VERSION ""

NS_ :

BS_:

BU_: Master pingpong

BO_ 386 pingpong_TPDO1: 4 pingpong
 SG_ UNSIGNED32_sent_from_slave : 0|32@1+ (1,0) [0|4294967295] "" Master

BO_ 514 pingpong_RPDO1: 4 Master
 SG_ UNSIGNED32_received_by_slave : 0|32@1+ (1,0) [0|4294967295] "" pingpong

BO_ 1794 pingpong_Heartbeat: 1 pingpong
 SG_ NMT_State : 0|7@1+ (1,0) [0|127] "" Master

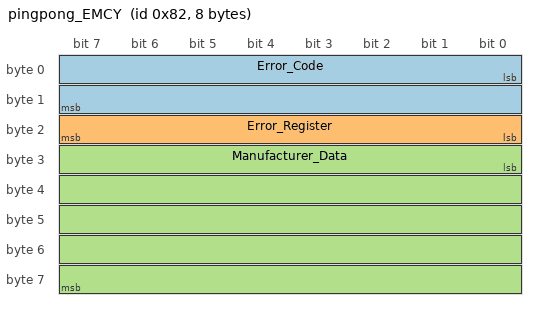
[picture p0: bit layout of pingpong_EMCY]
BO_ 130 pingpong_EMCY: 8 pingpong
 SG_ Error_Code : 0|16@1+ (1,0) [0|65535] "" Master
 SG_ Error_Register : 16|8@1+ (1,0) [0|255] "" Master
 SG_ Manufacturer_Data : 24|40@1+ (1,0) [0|1099511627775] "" Master

BO_ 0 NMT: 2 Master
 SG_ Command : 0|8@1+ (1,0) [0|255] "" pingpong
 SG_ Node_ID : 8|8@1+ (1,0) [0|255] "" pingpong

BO_ 128 SYNC: 0 Master

CM_ "CANopen network of canopen_config.json, exported by openplc-canopen-deploy TEST";
CM_ BO_ 386 "node 2 TPDO 1, transmission 1 from EDS";
CM_ SG_ 386 UNSIGNED32_sent_from_slave "0x4001:0 UNSIGNED32 -> %ID100";
CM_ BO_ 514 "node 2 RPDO 1, transmission 1 from EDS";
CM_ SG_ 514 UNSIGNED32_received_by_slave "0x4000:0 UNSIGNED32 -> %QD100";
CM_ BO_ 1794 "node 2 heartbeat";
CM_ BO_ 130 "node 2 emergency";
CM_ BO_ 0 "NMT node control; Node_ID 0 addresses all nodes";
CM_ BO_ 128 "SYNC";
BA_DEF_ BO_ "GenMsgCycleTime" INT 0 65535;
BA_DEF_DEF_ "GenMsgCycleTime" 0;
BA_ "GenMsgCycleTime" BO_ 386 100;
BA_ "GenMsgCycleTime" BO_ 514 100;
VAL_ 1794 NMT_State 0 "Boot-up" 4 "Stopped" 5 "Operational" 127 "Pre-operational" ;
VAL_ 0 Command 1 "Start" 2 "Stop" 128 "Enter pre-operational" 129 "Reset node" 130 "Reset communication" ;
